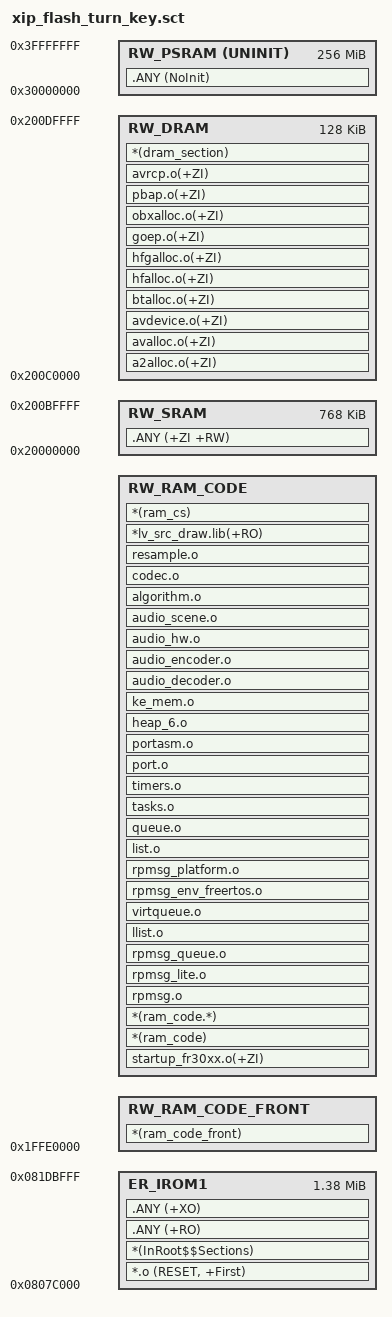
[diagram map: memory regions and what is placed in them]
; *************************************************************
; *** Scatter-Loading Description File generated by uVision ***
; *************************************************************

LR_IROM1 0x0807C000 0x00160000  {    ; load region size_region
  ER_IROM1 0x0807C000 0x00160000  {  ; load address = execution address
   *.o (RESET, +First)
   *(InRoot$$Sections)
   .ANY (+RO)
   .ANY (+XO)
  }

  RW_RAM_CODE_FRONT 0x1FFE0000  {
    *(ram_code_front)
  }
  RW_RAM_CODE +0 {
   startup_fr30xx.o(+ZI)
   *(ram_code)
   *(ram_code.*)
   
   rpmsg.o
   rpmsg_lite.o
   rpmsg_queue.o
   llist.o
   virtqueue.o
   rpmsg_env_freertos.o
   rpmsg_platform.o
   
   list.o
   queue.o
   tasks.o
   timers.o
   port.o
   portasm.o
   heap_6.o
   ke_mem.o
   
   audio_decoder.o
   audio_encoder.o
   audio_hw.o
   audio_scene.o
   algorithm.o
   codec.o
   resample.o
   
   *lv_src_draw.lib(+RO)
   *(ram_cs)
  }

  RW_SRAM 0x20000000 0x000c0000 {
    .ANY (+ZI +RW)
  }

  RW_DRAM 0x200c0000 0x00020000  {
    a2alloc.o(+ZI)
    avalloc.o(+ZI)
    avdevice.o(+ZI)
    btalloc.o(+ZI)
    hfalloc.o(+ZI)
    hfgalloc.o(+ZI)
    goep.o(+ZI)
    obxalloc.o(+ZI)
    pbap.o(+ZI)
    avrcp.o(+ZI)
    *(dram_section)
  }

  RW_PSRAM 0x30000000 UNINIT 0x10000000 {  ; RW data
   .ANY (NoInit)
  }

  ScatterAssert((ImageLength(RW_RAM_CODE_FRONT)+ImageLength(RW_RAM_CODE)) <= 0x20000)
}

